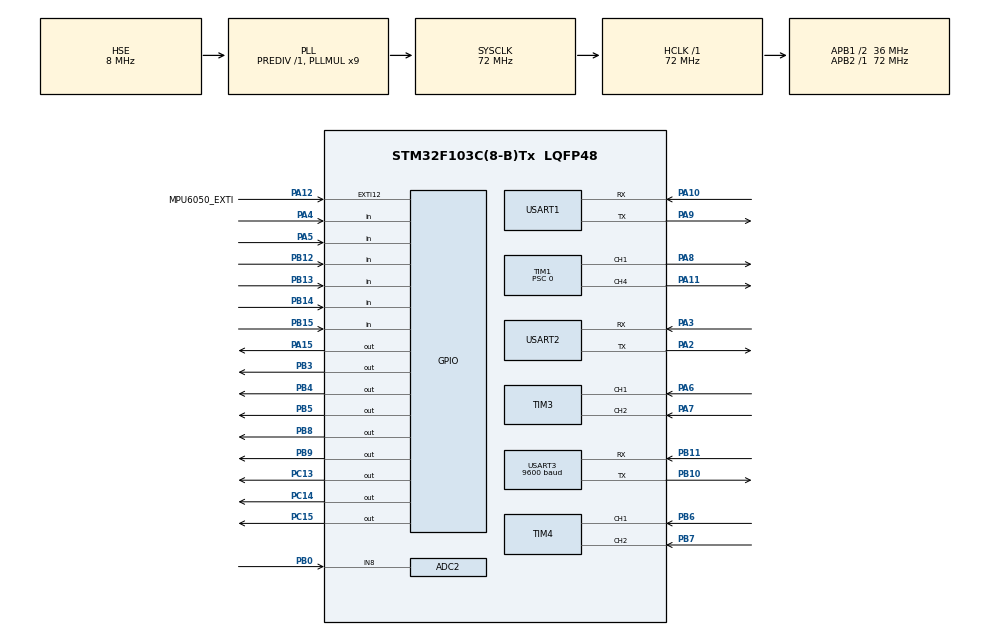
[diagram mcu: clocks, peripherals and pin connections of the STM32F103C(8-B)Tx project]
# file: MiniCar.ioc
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ADC2.Channel-0\#ChannelRegularConversion=ADC_CHANNEL_8
ADC2.NbrOfConversionFlag=1
ADC2.Rank-0\#ChannelRegularConversion=1
ADC2.SamplingTime-0\#ChannelRegularConversion=ADC_SAMPLETIME_1CYCLE_5
Mcu.Family=STM32F1
Mcu.Name=STM32F103C(8-B)Tx
Mcu.Package=LQFP48
NVIC.EXTI15_10_IRQn=true\:2\:0\:true\:false\:true\:true\:true\:true
NVIC.PriorityGroup=NVIC_PRIORITYGROUP_2
NVIC.TIM3_IRQn=true\:1\:0\:true\:false\:true\:true\:true\:true
NVIC.TIM4_IRQn=true\:1\:0\:true\:false\:true\:true\:true\:true
NVIC.USART1_IRQn=true\:1\:0\:true\:false\:true\:true\:true\:true
NVIC.USART3_IRQn=true\:1\:0\:true\:false\:true\:true\:true\:true
PA10.Mode=Asynchronous
PA10.Signal=USART1_RX
PA11.Signal=S_TIM1_CH4
PA12.GPIO_Label=MPU6050_EXTI
PA12.Signal=GPXTI12
PA15.Signal=GPIO_Output
PA2.Mode=Asynchronous
PA2.Signal=USART2_TX
PA3.Mode=Asynchronous
PA3.Signal=USART2_RX
PA4.Signal=GPIO_Input
PA5.Signal=GPIO_Input
PA6.Signal=S_TIM3_CH1
PA7.Signal=S_TIM3_CH2
PA8.Signal=S_TIM1_CH1
PA9.Mode=Asynchronous
PA9.Signal=USART1_TX
PB0.Signal=ADCx_IN8
PB10.Mode=Asynchronous
PB10.Signal=USART3_TX
PB11.Mode=Asynchronous
PB11.Signal=USART3_RX
PB12.Signal=GPIO_Input
PB13.Signal=GPIO_Input
PB14.Signal=GPIO_Input
PB15.Signal=GPIO_Input
PB3.Signal=GPIO_Output
PB4.Signal=GPIO_Output
PB5.Signal=GPIO_Output
PB6.Signal=S_TIM4_CH1
PB7.Signal=S_TIM4_CH2
PB8.Signal=GPIO_Output
PB9.Signal=GPIO_Output
PC13-TAMPER-RTC.Signal=GPIO_Output
PC14-OSC32_IN.Signal=GPIO_Output
PC15-OSC32_OUT.Signal=GPIO_Output
PD0-OSC_IN.Mode=HSE-External-Oscillator
PD0-OSC_IN.Signal=RCC_OSC_IN
PD1-OSC_OUT.Mode=HSE-External-Oscillator
PD1-OSC_OUT.Signal=RCC_OSC_OUT
ProjectManager.HeapSize=0x200
ProjectManager.StackSize=0x400
ProjectManager.TargetToolchain=MDK-ARM V5.32
RCC.ADCPresc=RCC_ADCPCLK2_DIV6
RCC.AHBFreq_Value=72000000
RCC.APB1CLKDivider=RCC_HCLK_DIV2
RCC.APB1Freq_Value=36000000
RCC.APB1TimFreq_Value=72000000
RCC.APB2Freq_Value=72000000
RCC.APB2TimFreq_Value=72000000
RCC.HCLKFreq_Value=72000000
RCC.PLLMUL=RCC_PLL_MUL9
RCC.PLLSourceVirtual=RCC_PLLSOURCE_HSE
RCC.SYSCLKFreq_VALUE=72000000
RCC.SYSCLKSource=RCC_SYSCLKSOURCE_PLLCLK
RCC.USBFreq_Value=72000000
SH.ADCx_IN8.0=ADC2_IN8,IN8
SH.S_TIM1_CH1.0=TIM1_CH1,PWM Generation1 CH1
SH.S_TIM1_CH4.0=TIM1_CH4,PWM Generation4 CH4
SH.S_TIM3_CH1.0=TIM3_CH1,Encoder_Interface
SH.S_TIM3_CH2.0=TIM3_CH2,Encoder_Interface
SH.S_TIM4_CH1.0=TIM4_CH1,Encoder_Interface
SH.S_TIM4_CH2.0=TIM4_CH2,Encoder_Interface
TIM1.AutoReloadPreload=TIM_AUTORELOAD_PRELOAD_ENABLE
TIM1.Channel-PWM\ Generation1\ CH1=TIM_CHANNEL_1
TIM1.Channel-PWM\ Generation4\ CH4=TIM_CHANNEL_4
TIM1.Period=7199
TIM1.Prescaler=0
TIM3.EncoderMode=TIM_ENCODERMODE_TI12
TIM4.EncoderMode=TIM_ENCODERMODE_TI12
USART1.VirtualMode=VM_ASYNC
USART2.VirtualMode=VM_ASYNC
USART3.BaudRate=9600
USART3.VirtualMode=VM_ASYNC
VP_SYS_VS_ND.Mode=No_Debug
board=custom

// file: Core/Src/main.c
/* USER CODE BEGIN Header */
/**
  ******************************************************************************
  * @file           : main.c
  * @brief          : Main program body
  ******************************************************************************
  * @attention
  *
  * Copyright (c) 2026 STMicroelectronics.
  * All rights reserved.
  *
  * This software is licensed under terms that can be found in the LICENSE file
  * in the root directory of this software component.
  * If no LICENSE file comes with this software, it is provided AS-IS.
  *
  ******************************************************************************
  */
/* USER CODE END Header */
#include "main.h"
#include "adc.h"
#include "tim.h"
#include "usart.h"
#include "gpio.h"

/* USER CODE BEGIN Includes */
#include "sys.h"
/* USER CODE END Includes */

void SystemClock_Config(void);

int main(void)
{

  /* MCU Configuration--------------------------------------------------------*/

  /* Reset of all peripherals, Initializes the Flash interface and the Systick. */
  HAL_Init();

  /* Configure the system clock */
  SystemClock_Config();

  /* Initialize all configured peripherals */
  MX_GPIO_Init();
  MX_USART1_UART_Init();
  MX_USART2_UART_Init();
  MX_USART3_UART_Init();
  MX_ADC2_Init();
  MX_TIM1_Init();
  MX_TIM3_Init();
  MX_TIM4_Init();
  /* USER CODE BEGIN 2 */
	JTAG_Set(JTAG_SWD_DISABLE);     //关闭JTAG接口
	JTAG_Set(SWD_ENABLE);           //打开SWD接口 可以利用主板的SWD接口调试
  delay_init();                   //延迟函数初始化
  OLED_Init();
	HAL_NVIC_EnableIRQ(EXTI15_10_IRQn);
  /* USER CODE END 2 */

  /* Infinite loop */
  /* USER CODE BEGIN WHILE */
  while (1)
  {
    OLED_ShowString(0,10,"hello world");
		OLED_Refresh_Gram();
		/* USER CODE END WHILE */

  }
}

void SystemClock_Config(void)
{
  RCC_OscInitTypeDef RCC_OscInitStruct = {0};
  RCC_ClkInitTypeDef RCC_ClkInitStruct = {0};
  RCC_PeriphCLKInitTypeDef PeriphClkInit = {0};

  /** Initializes the RCC Oscillators according to the specified parameters
  * in the RCC_OscInitTypeDef structure.
  */
  RCC_OscInitStruct.OscillatorType = RCC_OSCILLATORTYPE_HSE;
  RCC_OscInitStruct.HSEState = RCC_HSE_ON;
  RCC_OscInitStruct.HSEPredivValue = RCC_HSE_PREDIV_DIV1;
  RCC_OscInitStruct.HSIState = RCC_HSI_ON;
  RCC_OscInitStruct.PLL.PLLState = RCC_PLL_ON;
  RCC_OscInitStruct.PLL.PLLSource = RCC_PLLSOURCE_HSE;
  RCC_OscInitStruct.PLL.PLLMUL = RCC_PLL_MUL9;
  if (HAL_RCC_OscConfig(&RCC_OscInitStruct) != HAL_OK)
  {
    Error_Handler();
  }

  /** Initializes the CPU, AHB and APB buses clocks
  */
  RCC_ClkInitStruct.ClockType = RCC_CLOCKTYPE_HCLK|RCC_CLOCKTYPE_SYSCLK
                              |RCC_CLOCKTYPE_PCLK1|RCC_CLOCKTYPE_PCLK2;
  RCC_ClkInitStruct.SYSCLKSource = RCC_SYSCLKSOURCE_PLLCLK;
  RCC_ClkInitStruct.AHBCLKDivider = RCC_SYSCLK_DIV1;
  RCC_ClkInitStruct.APB1CLKDivider = RCC_HCLK_DIV2;
  RCC_ClkInitStruct.APB2CLKDivider = RCC_HCLK_DIV1;

  if (HAL_RCC_ClockConfig(&RCC_ClkInitStruct, FLASH_LATENCY_2) != HAL_OK)
  {
    Error_Handler();
  }
  PeriphClkInit.PeriphClockSelection = RCC_PERIPHCLK_ADC;
  PeriphClkInit.AdcClockSelection = RCC_ADCPCLK2_DIV6;
  if (HAL_RCCEx_PeriphCLKConfig(&PeriphClkInit) != HAL_OK)
  {
    Error_Handler();
  }
}

void Error_Handler(void)
{
  __disable_irq();
  while (1)
  {
  }
}
